# nrf9220_application register map
Vendor: Nordic Semiconductor; Series: nRF92; File version: 1
CPU: CM33 r0p4, little endian, MPU, FPU, 3 interrupt priority bits, 480 interrupts, 4 SAU regions
Registers are 32-bit, read-write, reset 0x0 unless marked. A register's access mark holds for its fields unless they carry their own. Offsets are from the block's base; [hi:lo] are bit positions; lines under a group give offsets from that group; {n}, {i} and the like mark numbered series; 'fields as' and 'values as' point back to an identical list.

## GLOBAL_SIMIF130_NS — SIM card interface 0
Base 0x4F996000
Same registers: GLOBAL_SIMIF130_S 0x5F996000
0x00 TASKS_DMASTARTRX wo — Start DMA transfer from SIM card to memory
  [0] TASKS_DMASTARTRX
    1=Trigger task
0x04 TASKS_DMASTOPRX wo — Stop DMA transfer from SIM card to memory
  [0] TASKS_DMASTOPRX
    1=Trigger task
0x08 TASKS_DMASTARTTX wo — Start DMA transfer from memory to SIM card
  [0] TASKS_DMASTARTTX
    1=Trigger task
0x0C TASKS_DMASTOPTX wo — Stop DMA transfer from memory to SIM card
  [0] TASKS_DMASTOPTX
    1=Trigger task
0x10 TASKS_RSTSET wo — Set SIM card reset signal
  [0] TASKS_RSTSET
    1=Trigger task
0x14 TASKS_RSTCLEAR wo — Clear SIM card reset signal
  [0] TASKS_RSTCLEAR
    1=Trigger task
0x18 TASKS_RESET wo — Reset everything
  [0] TASKS_RESET
    1=Trigger task
0x1C TASKS_UARTRX wo — Start Uart for Rx access
  [0] TASKS_UARTRX
    1=Trigger task
0x20 TASKS_UARTTX wo — Start Uart for Tx access
  [0] TASKS_UARTTX
    1=Trigger task
0x24 TASKS_STARTWRITEFROMREG wo — Write test data from Ahb test reg to Ahb Rx bus
  [0] TASKS_STARTWRITEFROMREG
    1=Trigger task
0x28 TASKS_STARTREADTOREG wo — Read data from Ahb Tx bus to Ahb test reg
  [0] TASKS_STARTREADTOREG
    1=Trigger task
0x2C TASKS_PROTOCOLT0SET wo — Start using protocol T0
  [0] TASKS_PROTOCOLT0SET
    1=Trigger task
0x30 TASKS_PROTOCOLT1SET wo — Start using protocol T1
  [0] TASKS_PROTOCOLT1SET
    1=Trigger task
0x34 TASKS_PROTOCOLNONSET wo — Start using protocol none
  [0] TASKS_PROTOCOLNONSET
    1=Trigger task
0x38 TASKS_TIMECOUNTCLEAR wo — Stop and clear time out counter
  [0] TASKS_TIMECOUNTCLEAR
    1=Trigger task
0x80 TASKS_UART group — Peripheral tasks.
  0x00 SUSPEND wo — Suspend UART
    [0] SUSPEND
      1=Trigger task
  0x04 RESUME wo — Resume UART
    [0] RESUME
      1=Trigger task
  0x0C STOPRX wo — Stop UART data reception
    [0] STOPRX
      1=Trigger task
  0x14 STOPTX wo — Stop UART data transmission
    [0] STOPTX
      1=Trigger task
  0x18 STARTTRX wo — Start UART data transmission and reception
    [0] STARTTRX
      1=Trigger task
  0x1C STOPTRX wo — Stop UART data transmission and reception
    [0] STOPTRX
      1=Trigger task
0x100 EVENTS_DMA group — Peripheral events.
  0x00 RXSTARTED — DMA Rx operation started
    [0] RXSTARTED
      0=NotGenerated (Event not generated); 1=Generated (Event generated)
  0x04 RXDONE — DMA Rx operation finished
    [0] RXDONE
      values as EVENTS_DMA.RXSTARTED.RXSTARTED
  0x08 TXSTARTED — DMA Tx operation started
    [0] TXSTARTED
      values as EVENTS_DMA.RXSTARTED.RXSTARTED
  0x0C TXDONE — DMA Tx operation finished
    [0] TXDONE
      values as EVENTS_DMA.RXSTARTED.RXSTARTED
0x110 EVENTS_INVALIDCONVENTION — ATR.TS convention not recognized
  [0] EVENTS_INVALIDCONVENTION
    values as EVENTS_DMA.RXSTARTED.RXSTARTED
0x114 EVENTS_PARITYERROR — Tx or Rx byte parity error
  [0] EVENTS_PARITYERROR
    values as EVENTS_DMA.RXSTARTED.RXSTARTED
0x118 EVENTS_ATRTIMEOUT — No ATR between 400 and 40000 sim clock cycles
  [0] EVENTS_ATRTIMEOUT
    values as EVENTS_DMA.RXSTARTED.RXSTARTED
0x11C EVENTS_CWTIMEOUT — T=1 character wait timeout
  [0] EVENTS_CWTIMEOUT
    values as EVENTS_DMA.RXSTARTED.RXSTARTED
0x120 EVENTS_BWTIMEOUT — T=1 block wait timeout or T=0 wait timeout
  [0] EVENTS_BWTIMEOUT
    values as EVENTS_DMA.RXSTARTED.RXSTARTED
0x124 EVENTS_SW1SW2 — SW1 and SW2 bytes received
  [0] EVENTS_SW1SW2
    values as EVENTS_DMA.RXSTARTED.RXSTARTED
0x128 EVENTS_RESET — Everything reset
  [0] EVENTS_RESET
    values as EVENTS_DMA.RXSTARTED.RXSTARTED
0x12C EVENTS_INS — T=0 procedure byte INS received
  [0] EVENTS_INS
    values as EVENTS_DMA.RXSTARTED.RXSTARTED
0x130 EVENTS_NINS — T=0 procedure byte !INS received
  [0] EVENTS_NINS
    values as EVENTS_DMA.RXSTARTED.RXSTARTED
0x134 EVENTS_ERROR — Error response
  [0] EVENTS_ERROR
    values as EVENTS_DMA.RXSTARTED.RXSTARTED
0x138 EVENTS_READYTX — Byte sent after START_WRITE_FROM_REG
  [0] EVENTS_READYTX
    values as EVENTS_DMA.RXSTARTED.RXSTARTED
0x13C EVENTS_RXDATAREADY — Byte received after START_READ_TO_REG
  [0] EVENTS_RXDATAREADY
    values as EVENTS_DMA.RXSTARTED.RXSTARTED
0x140 EVENTS_T1RXOVERRUN — Unexpected bytes received after DMA RX[0...N], SW1SW2 in T=1
  [0] EVENTS_T1RXOVERRUN
    values as EVENTS_DMA.RXSTARTED.RXSTARTED
0x144 EVENTS_T1TXABORTED — T=1 card responded with S (ABORT request)
  [0] EVENTS_T1TXABORTED
    values as EVENTS_DMA.RXSTARTED.RXSTARTED
0x148 EVENTS_T1NONIBLOCK — T=1 unrecognized (S or R) block (with correct LRC) stored in RX_DATA
  [0] EVENTS_T1NONIBLOCK
    values as EVENTS_DMA.RXSTARTED.RXSTARTED
0x14C EVENTS_T1LENERROR — T=1 LEN = 255
  [0] EVENTS_T1LENERROR
    values as EVENTS_DMA.RXSTARTED.RXSTARTED
0x150 EVENTS_EDCERROR — T=1 EDC error
  [0] EVENTS_EDCERROR
    values as EVENTS_DMA.RXSTARTED.RXSTARTED
0x154 EVENTS_NADERROR — T=1 NAD error
  [0] EVENTS_NADERROR
    values as EVENTS_DMA.RXSTARTED.RXSTARTED
0x158 EVENTS_ERRORCOUNTMAX — Number of unsuccessful Rx or Tx operations equals max value
  [0] EVENTS_ERRORCOUNTMAX
    values as EVENTS_DMA.RXSTARTED.RXSTARTED
0x15C EVENTS_T1RXMORE — More bit high in PCB of Rx T=1 I block
  [0] EVENTS_T1RXMORE
    values as EVENTS_DMA.RXSTARTED.RXSTARTED
0x160 EVENTS_T1RXFRAMEEND — Len byte + 1 bytes of T1 Rx data received
  [0] EVENTS_T1RXFRAMEEND
    values as EVENTS_DMA.RXSTARTED.RXSTARTED
0x164 EVENTS_DMA2 group — Peripheral events.
  0x00 RXERRORRESP — DMA Rx bus transfer error response
    [0] RXERRORRESP
      values as EVENTS_DMA.RXSTARTED.RXSTARTED
  0x04 TXERRORRESP — DMA Tx bus transfer error response
    [0] TXERRORRESP
      values as EVENTS_DMA.RXSTARTED.RXSTARTED
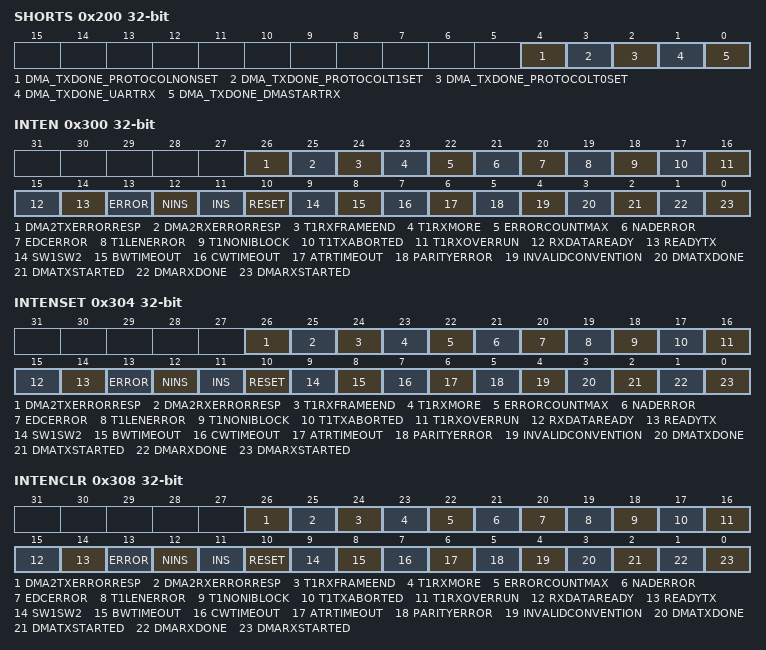
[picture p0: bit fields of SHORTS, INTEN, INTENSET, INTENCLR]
0x200 SHORTS — Shortcuts between local events and tasks
  [all] fields
    0=Disabled (Disable shortcut); 1=Enabled (Enable shortcut)
  [4] DMA_TXDONE_PROTOCOLNONSET — Shortcut between event DMA.TXDONE and task PROTOCOLNONSET
  [3] DMA_TXDONE_PROTOCOLT1SET — Shortcut between event DMA.TXDONE and task PROTOCOLT1SET
  [2] DMA_TXDONE_PROTOCOLT0SET — Shortcut between event DMA.TXDONE and task PROTOCOLT0SET
  [1] DMA_TXDONE_UARTRX — Shortcut between event DMA.TXDONE and task UARTRX
  [0] DMA_TXDONE_DMASTARTRX — Shortcut between event DMA.TXDONE and task DMASTARTRX
0x300 INTEN — Enable or disable interrupt
  [all] fields
    0=Disabled; 1=Enabled
  [26] DMA2TXERRORRESP — Enable or disable interrupt for event DMA2TXERRORRESP
  [25] DMA2RXERRORRESP — Enable or disable interrupt for event DMA2RXERRORRESP
  [24] T1RXFRAMEEND — Enable or disable interrupt for event T1RXFRAMEEND
  [23] T1RXMORE — Enable or disable interrupt for event T1RXMORE
  [22] ERRORCOUNTMAX — Enable or disable interrupt for event ERRORCOUNTMAX
  [21] NADERROR — Enable or disable interrupt for event NADERROR
  [20] EDCERROR — Enable or disable interrupt for event EDCERROR
  [19] T1LENERROR — Enable or disable interrupt for event T1LENERROR
  [18] T1NONIBLOCK — Enable or disable interrupt for event T1NONIBLOCK
  [17] T1TXABORTED — Enable or disable interrupt for event T1TXABORTED
  [16] T1RXOVERRUN — Enable or disable interrupt for event T1RXOVERRUN
  [15] RXDATAREADY — Enable or disable interrupt for event RXDATAREADY
  [14] READYTX — Enable or disable interrupt for event READYTX
  [13] ERROR — Enable or disable interrupt for event ERROR
  [12] NINS — Enable or disable interrupt for event NINS
  [11] INS — Enable or disable interrupt for event INS
  [10] RESET — Enable or disable interrupt for event RESET
  [9] SW1SW2 — Enable or disable interrupt for event SW1SW2
  [8] BWTIMEOUT — Enable or disable interrupt for event BWTIMEOUT
  [7] CWTIMEOUT — Enable or disable interrupt for event CWTIMEOUT
  [6] ATRTIMEOUT — Enable or disable interrupt for event ATRTIMEOUT
  [5] PARITYERROR — Enable or disable interrupt for event PARITYERROR
  [4] INVALIDCONVENTION — Enable or disable interrupt for event INVALIDCONVENTION
  [3] DMATXDONE — Enable or disable interrupt for event DMATXDONE
  [2] DMATXSTARTED — Enable or disable interrupt for event DMATXSTARTED
  [1] DMARXDONE — Enable or disable interrupt for event DMARXDONE
  [0] DMARXSTARTED — Enable or disable interrupt for event DMARXSTARTED
0x304 INTENSET — Enable interrupt
  [all] fields
    on read: 0=Disabled (Read: Disabled); 1=Enabled (Read: Enabled) | on write: 1=Set (Enable)
  [26] DMA2TXERRORRESP — Write '1' to enable interrupt for event DMA2TXERRORRESP
  [25] DMA2RXERRORRESP — Write '1' to enable interrupt for event DMA2RXERRORRESP
  [24] T1RXFRAMEEND — Write '1' to enable interrupt for event T1RXFRAMEEND
  [23] T1RXMORE — Write '1' to enable interrupt for event T1RXMORE
  [22] ERRORCOUNTMAX — Write '1' to enable interrupt for event ERRORCOUNTMAX
  [21] NADERROR — Write '1' to enable interrupt for event NADERROR
  [20] EDCERROR — Write '1' to enable interrupt for event EDCERROR
  [19] T1LENERROR — Write '1' to enable interrupt for event T1LENERROR
  [18] T1NONIBLOCK — Write '1' to enable interrupt for event T1NONIBLOCK
  [17] T1TXABORTED — Write '1' to enable interrupt for event T1TXABORTED
  [16] T1RXOVERRUN — Write '1' to enable interrupt for event T1RXOVERRUN
  [15] RXDATAREADY — Write '1' to enable interrupt for event RXDATAREADY
  [14] READYTX — Write '1' to enable interrupt for event READYTX
  [13] ERROR — Write '1' to enable interrupt for event ERROR
  [12] NINS — Write '1' to enable interrupt for event NINS
  [11] INS — Write '1' to enable interrupt for event INS
  [10] RESET — Write '1' to enable interrupt for event RESET
  [9] SW1SW2 — Write '1' to enable interrupt for event SW1SW2
  [8] BWTIMEOUT — Write '1' to enable interrupt for event BWTIMEOUT
  [7] CWTIMEOUT — Write '1' to enable interrupt for event CWTIMEOUT
  [6] ATRTIMEOUT — Write '1' to enable interrupt for event ATRTIMEOUT
  [5] PARITYERROR — Write '1' to enable interrupt for event PARITYERROR
  [4] INVALIDCONVENTION — Write '1' to enable interrupt for event INVALIDCONVENTION
  [3] DMATXDONE — Write '1' to enable interrupt for event DMATXDONE
  [2] DMATXSTARTED — Write '1' to enable interrupt for event DMATXSTARTED
  [1] DMARXDONE — Write '1' to enable interrupt for event DMARXDONE
  [0] DMARXSTARTED — Write '1' to enable interrupt for event DMARXSTARTED
0x308 INTENCLR — Disable interrupt
  [all] fields
    on read: 0=Disabled (Read: Disabled); 1=Enabled (Read: Enabled) | on write: 1=Clear (Disable)
  [26] DMA2TXERRORRESP — Write '1' to disable interrupt for event DMA2TXERRORRESP
  [25] DMA2RXERRORRESP — Write '1' to disable interrupt for event DMA2RXERRORRESP
  [24] T1RXFRAMEEND — Write '1' to disable interrupt for event T1RXFRAMEEND
  [23] T1RXMORE — Write '1' to disable interrupt for event T1RXMORE
  [22] ERRORCOUNTMAX — Write '1' to disable interrupt for event ERRORCOUNTMAX
  [21] NADERROR — Write '1' to disable interrupt for event NADERROR
  [20] EDCERROR — Write '1' to disable interrupt for event EDCERROR
  [19] T1LENERROR — Write '1' to disable interrupt for event T1LENERROR
  [18] T1NONIBLOCK — Write '1' to disable interrupt for event T1NONIBLOCK
  [17] T1TXABORTED — Write '1' to disable interrupt for event T1TXABORTED
  [16] T1RXOVERRUN — Write '1' to disable interrupt for event T1RXOVERRUN
  [15] RXDATAREADY — Write '1' to disable interrupt for event RXDATAREADY
  [14] READYTX — Write '1' to disable interrupt for event READYTX
  [13] ERROR — Write '1' to disable interrupt for event ERROR
  [12] NINS — Write '1' to disable interrupt for event NINS
  [11] INS — Write '1' to disable interrupt for event INS
  [10] RESET — Write '1' to disable interrupt for event RESET
  [9] SW1SW2 — Write '1' to disable interrupt for event SW1SW2
  [8] BWTIMEOUT — Write '1' to disable interrupt for event BWTIMEOUT
  [7] CWTIMEOUT — Write '1' to disable interrupt for event CWTIMEOUT
  [6] ATRTIMEOUT — Write '1' to disable interrupt for event ATRTIMEOUT
  [5] PARITYERROR — Write '1' to disable interrupt for event PARITYERROR
  [4] INVALIDCONVENTION — Write '1' to disable interrupt for event INVALIDCONVENTION
  [3] DMATXDONE — Write '1' to disable interrupt for event DMATXDONE
  [2] DMATXSTARTED — Write '1' to disable interrupt for event DMATXSTARTED
  [1] DMARXDONE — Write '1' to disable interrupt for event DMARXDONE
  [0] DMARXSTARTED — Write '1' to disable interrupt for event DMARXSTARTED
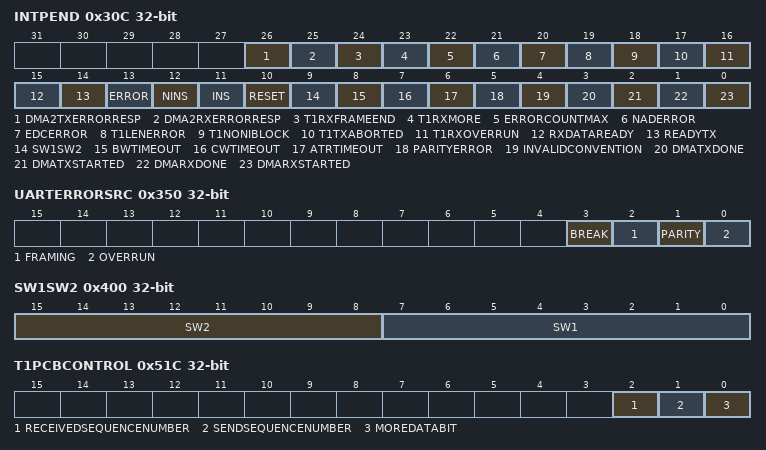
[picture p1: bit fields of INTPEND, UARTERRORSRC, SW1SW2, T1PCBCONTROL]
0x30C INTPEND ro — Pending interrupts
  [all] fields
    on read: 0=NotPending (Read: Not pending); 1=Pending (Read: Pending)
  [26] DMA2TXERRORRESP — Read pending status of interrupt for event DMA2TXERRORRESP
  [25] DMA2RXERRORRESP — Read pending status of interrupt for event DMA2RXERRORRESP
  [24] T1RXFRAMEEND — Read pending status of interrupt for event T1RXFRAMEEND
  [23] T1RXMORE — Read pending status of interrupt for event T1RXMORE
  [22] ERRORCOUNTMAX — Read pending status of interrupt for event ERRORCOUNTMAX
  [21] NADERROR — Read pending status of interrupt for event NADERROR
  [20] EDCERROR — Read pending status of interrupt for event EDCERROR
  [19] T1LENERROR — Read pending status of interrupt for event T1LENERROR
  [18] T1NONIBLOCK — Read pending status of interrupt for event T1NONIBLOCK
  [17] T1TXABORTED — Read pending status of interrupt for event T1TXABORTED
  [16] T1RXOVERRUN — Read pending status of interrupt for event T1RXOVERRUN
  [15] RXDATAREADY — Read pending status of interrupt for event RXDATAREADY
  [14] READYTX — Read pending status of interrupt for event READYTX
  [13] ERROR — Read pending status of interrupt for event ERROR
  [12] NINS — Read pending status of interrupt for event NINS
  [11] INS — Read pending status of interrupt for event INS
  [10] RESET — Read pending status of interrupt for event RESET
  [9] SW1SW2 — Read pending status of interrupt for event SW1SW2
  [8] BWTIMEOUT — Read pending status of interrupt for event BWTIMEOUT
  [7] CWTIMEOUT — Read pending status of interrupt for event CWTIMEOUT
  [6] ATRTIMEOUT — Read pending status of interrupt for event ATRTIMEOUT
  [5] PARITYERROR — Read pending status of interrupt for event PARITYERROR
  [4] INVALIDCONVENTION — Read pending status of interrupt for event INVALIDCONVENTION
  [3] DMATXDONE — Read pending status of interrupt for event DMATXDONE
  [2] DMATXSTARTED — Read pending status of interrupt for event DMATXSTARTED
  [1] DMARXDONE — Read pending status of interrupt for event DMARXDONE
  [0] DMARXSTARTED — Read pending status of interrupt for event DMARXSTARTED
0x350 UARTERRORSRC write-1-clears — Error source
  [all] fields
    on read: 0=NotPresent (Read: error not present); 1=Present (Read: error present)
  [3] BREAK — Break condition
  [2] FRAMING — Framing error occurred
  [1] PARITY — Parity error
  [0] OVERRUN — Overrun error
0x400 SW1SW2 — Sw1 and Sw2 bytes received from SIM card in T=1 mode
  [15:8] SW2 — Sw2 data byte received
  [7:0] SW1 — Sw1 data byte received
0x404 CONVENTION — Data convention used in traffic between controller and SIM card
  [0] DATACONVENTION — Data convention between controller and SIM card
    0=Direct convention: 1 = High, LSB first; 1=Inverse convention: 1 = Low, MSB first
0x408 LRCOUT — Latest generated LRC value
  [7:0] LRCOUT
0x40C RXDATA ro — NonDMA received data
  [7:0] RXDATA — NonDMA received data or Rx data of T=1 S block if RxBufferLength = 3
0x410 T0SWXCOUNT — Number of SWx bytes received after T=0 Rx DMA finished
  [1:0] T0SWXCOUNT
0x500 CLKRATE reset 0x5 — Divider value for setting the clock rate to the SIM card.
  [6:0] CLOCKRATE — Divider for setting the clock frequency to the SIM card clock (SIM card clock = input clock / ClockRate)
0x504 BAUDRATE reset 0x174 — Number of clock cycles per serial data bit. Equal to ISO standard F/D (clock rate conversion integer divided by baud rate adjustment integer).
  [8:0] BAUDRATE
0x508 CHARACTERGUARDTIME reset 0xC
  [7:0] CHARACTERGUARDTIME — Guard time from leading edge of the character to the leading edge of the next character in ETU
0x50C CHARACTERWAITTIME reset 0xD
  [15:0] CHARACTERWAITTIME — T=1 character Rx wait time in ETU
0x510 BLOCKWAITTIME reset 0x2580
  [26:0] BLOCKWAITTIME — T=1 block wait time. T=0 wait time. Unit is ETU. Default 9600
0x514 PROTOCOL — Protocol selection
  [1:0] PROTOCOL — Protocol selection 0: T=0, 1: T=1
    0=T0; 1=T1
0x518 LOWIMPEDANCE reset 0x1 — Low impedance driver use
  [0] LOWIMPEDANCE
    0=OpenDrain; 1=LowImpedance (Use low impedance drivers)
0x51C T1PCBCONTROL — T=1 Tx PCB bits 5:6
  [2] RECEIVEDSEQUENCENUMBER ro — Rx Send Sequence number in T1 I Block
  [1] SENDSEQUENCENUMBER — Send Sequence number, PCB[6]
  [0] MOREDATABIT — More data (chaining) bit, PCB[5]
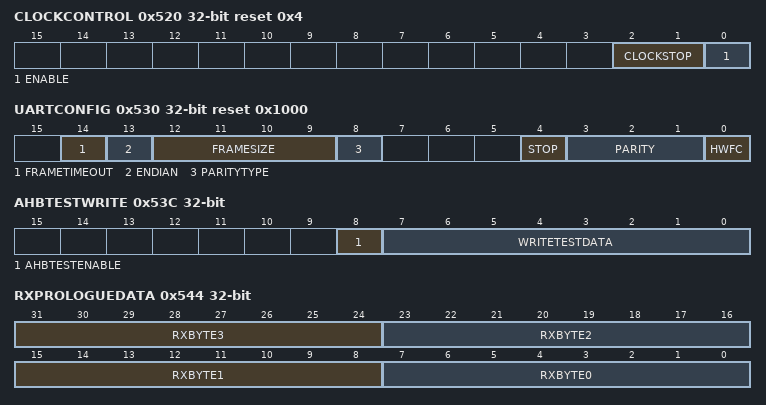
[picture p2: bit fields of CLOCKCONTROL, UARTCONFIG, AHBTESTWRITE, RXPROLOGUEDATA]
0x520 CLOCKCONTROL reset 0x4
  [2:1] CLOCKSTOP — Clock stop state
    0=Illegal (Not allowed); 1=High (Clock stops low); 2=Low (Clock stops high)
  [0] ENABLE — Enable clock
    0=ClockOff (Clock is off); 1=ClockOn (Clock is on)
0x524 VOLTAGE reset 0x1 — SIM card operating voltage
  [1:0] VOLTAGE
    0=0V (Card voltage off); 1=1800mV (Card operating voltage 1.8V); 2=3000mV (Card operating voltage 3V)
0x528 LRCENABLE — LRC Calculation enable
  [0] LRCENABLE — LRC Calculation enable for T=1
    0=Disable (LRC calculation disabled); 1=Enable (LRC calculation enabled)
0x52C TXDATA wo — NonDMA data to be sent to the SIM card
  [7:0] TXDATA
0x530 UARTCONFIG reset 0x1000 — Configuration of parity, hardware flow control, framesize, and packet timeout.
  [14] FRAMETIMEOUT — Enable packet timeout.
    0=DISABLED (Packet timeout is disabled.); 1=ENABLED (Packet timeout is enabled.); 0=Disabled (Packet timeout is disabled.); 1=Enabled (Packet timeout is enabled.)
  [13] ENDIAN — Select if data is trimmed from MSB or LSB end when the data frame size is less than 8.
    0=MSB (Data is trimmed from MSB end.); 1=LSB (Data is trimmed from LSB end.)
  [12:9] FRAMESIZE — Set the data frame size
    9=9 bit data frame size. 9th bit is treated as address bit.; {v}={v} bit data frame size (v=4..8)
  [8] PARITYTYPE — Even or odd parity type
    0=Even parity; 1=Odd (Odd parity)
  [4] STOP — Stop bits
    0=One (One stop bit); 1=Two (Two stop bits)
  [3:1] PARITY
    0=Excluded (Exclude parity bit); 7=Included (Include parity bit)
  [0] HWFC — Hardware flow control
    0=Disabled; 1=Enabled
0x534 WRITEMAXATT reset 0xA — Number of write attempts before error interrupt
  [7:0] WRITEMAXATT
0x538 READMAXATT reset 0xA — Number of read attempts before error interrupt
  [7:0] READMAXATT
0x53C AHBTESTWRITE — Test data to write through Ahb Rx bus
  [8] AHBTESTENABLE — Enable bit for Ahb testing, both read and write
  [7:0] WRITETESTDATA — Test data for Ahb write access for Ahb Rx bus
0x540 AHBTESTREAD ro — Test data to read through Ahb Tx bus
  [7:0] READTESTDATA — Test data read through Ahb Tx bus
0x544 RXPROLOGUEDATA — Four first Rx data bytes from card
  [31:24] RXBYTE3 — Fourth Rx byte from card
  [23:16] RXBYTE2 — Third Rx byte from card
  [15:8] RXBYTE1 — Second Rx byte from card
  [7:0] RXBYTE0 — First Rx byte from card
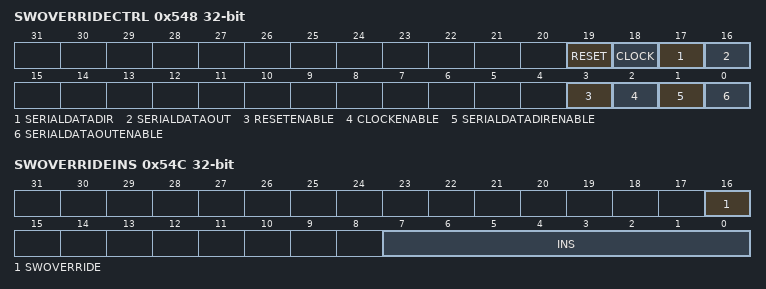
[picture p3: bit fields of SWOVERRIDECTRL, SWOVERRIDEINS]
0x548 SWOVERRIDECTRL — SW override for the output signals to I/O pads
  [19] RESET — Control for reset
    0=Low (Reset driven low); 1=High (Reset driven high)
  [18] CLOCK — Control for clock
    0=Low (Clock driven low); 1=High (Clock driven high)
  [17] SERIALDATADIR — Control for SerialDataDir
    0=InputMode (SerialDataDir driven low); 1=OutputMode (SerialDataDir driven high)
  [16] SERIALDATAOUT — Control for SerialDataOut
    0=Low (SerialDataOut driven low); 1=High (SerialDataOut driven high)
  [3] RESETENABLE — Enable for the override
    0=NormalOperation (Output controlled by the hardware. Override does not have effect.); 1=Override (Output controlled from the register)
  [2] CLOCKENABLE — Enable for the override
    values as RESETENABLE
  [1] SERIALDATADIRENABLE — Enable for the override
    values as RESETENABLE
  [0] SERIALDATAOUTENABLE — Enable for the override
    values as RESETENABLE
0x54C SWOVERRIDEINS — SW override for INS byte reference used to detect if card responds with INS or !INS
  [16] SWOVERRIDE
    0=NormalOperation (INS byte reference can be updated by HW. The current reference can still be modified through INS field.); 1=Override (INS byte reference will not be updated by HW)
  [7:0] INS — INS byte reference used to detect if card responds with INS or !INS
0x574 UARTENABLE
  [0] ENABLE — UART master enable
0x578 UARTRXENABLE wo
  [0] ENABLE — UART Rx enable
0x57C UARTTXENABLE wo
  [0] ENABLE — UART Tx enable
0x580 UARTADDRESS — Set address for Rx (when UART frame size is 9)
  [7:0] ADDRESS — UART address in 9b mode
0x584 UARTFRAMETIMEOUT reset 0x10 — Number of symbol periods before timeout
  [9:0] TIMEOUT
0x600 DMARXADDR — Rx DMA access buffer RAM start address
  [31:0] DMARXSTARTADDRESS
0x604 DMARXBUFFERSIZE — Byte count to receive in DMA Rx operation
  [8:0] DMARXBUFFERSIZE
0x608 DMARXBYTECOUNT ro — Byte count received in latest DMA Rx operation
  [8:0] DMARXBYTECOUNT
0x60C DMARXENABLE — Enable for Rx DMA
  [0] DMARXENABLE
0x610 DMARXSELECTLIST ro — Rx select address from list
  [1:0] DMARXSELECTLIST — Select address from list
0x614 DMARXCURRENTAMOUNT ro — Number of bytes transferred in the current transaction
  [10:0] AMOUNT — Number of bytes transferred in the current transaction. Continuously updated. Updated when data leaves the internal FIFO and is transferred to the destination.
0x618 DMARXMODE reset 0x1 — Configure EasyDMA mode
  [0] LPOP — Enable low-power operation, or use low-latency
    0=Low-latency operation; 1=Low-power operation
0x61C DMARXBUSERRORADDRESS ro — Address of transaction that generated the last BUSERROR event.
  [31:0] ADDRESS
0x700 DMATXADDR — Tx DMA access buffer RAM start address
  [31:0] DMATXSTARTADDRESS
0x704 DMATXBUFFERSIZE — Byte count to transmit in DMA Tx operation
  [8:0] DMATXBUFFERSIZE
0x708 DMATXBYTECOUNT ro — Byte count transmitted in latest DMA Tx operation
  [8:0] DMATXBYTECOUNT
0x70C DMATXENABLE — Enable for Tx DMA
  [0] DMATXENABLE
0x710 DMATXSELECTLIST ro — Tx select address from list
  [1:0] DMATXSELECTLIST — Select address from list
0x714 DMATXCURRENTAMOUNT ro — Number of bytes transferred in the current transaction
  fields as DMARXCURRENTAMOUNT
0x718 DMATXMODE reset 0x1 — Configure EasyDMA mode
  fields as DMARXMODE
0x71C DMATXBUSERRORADDRESS ro — Address of transaction that generated the last BUSERROR event.
  [31:0] ADDRESS
